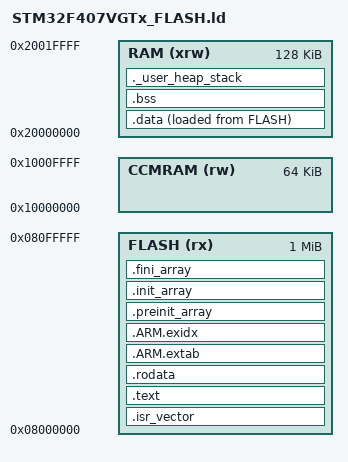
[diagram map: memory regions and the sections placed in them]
ENTRY(Reset_Handler)

_estack = ORIGIN(RAM) + LENGTH(RAM);
_Min_Heap_Size = 0x200;
_Min_Stack_Size = 0x800;

MEMORY
{
  FLASH (rx)  : ORIGIN = 0x08000000, LENGTH = 1024K
  /* SRAM1 (112 KiB) and SRAM2 (16 KiB) are contiguous. */
  RAM   (xrw) : ORIGIN = 0x20000000, LENGTH = 128K
  /* The remaining 64 KiB is core-coupled memory at a separate address. */
  CCMRAM (rw) : ORIGIN = 0x10000000, LENGTH = 64K
}

PHDRS
{
  flash PT_LOAD FLAGS(5);
  ram PT_LOAD FLAGS(6);
}

SECTIONS
{
  .isr_vector : { . = ALIGN(4); KEEP(*(.isr_vector)) . = ALIGN(4); } >FLASH :flash
  .text :
  {
    . = ALIGN(4);
    *(.text) *(.text*) *(.glue_7) *(.glue_7t) *(.eh_frame)
    KEEP(*(.init)) KEEP(*(.fini))
    . = ALIGN(4);
    _etext = .;
  } >FLASH
  .rodata : { . = ALIGN(4); *(.rodata) *(.rodata*) . = ALIGN(4); } >FLASH
  .ARM.extab : { *(.ARM.extab* .gnu.linkonce.armextab.*) } >FLASH
  .ARM.exidx : { __exidx_start = .; *(.ARM.exidx*) __exidx_end = .; } >FLASH
  .preinit_array : { PROVIDE_HIDDEN(__preinit_array_start = .); KEEP(*(.preinit_array*)) PROVIDE_HIDDEN(__preinit_array_end = .); } >FLASH
  .init_array : { PROVIDE_HIDDEN(__init_array_start = .); KEEP(*(SORT(.init_array.*))) KEEP(*(.init_array*)) PROVIDE_HIDDEN(__init_array_end = .); } >FLASH
  .fini_array : { PROVIDE_HIDDEN(__fini_array_start = .); KEEP(*(SORT(.fini_array.*))) KEEP(*(.fini_array*)) PROVIDE_HIDDEN(__fini_array_end = .); } >FLASH
  _sidata = LOADADDR(.data);
  .data :
  {
    . = ALIGN(4); _sdata = .;
    *(.data) *(.data*)
    . = ALIGN(4); _edata = .;
  } >RAM AT> FLASH :ram
  .bss (NOLOAD) :
  {
    . = ALIGN(4); _sbss = .; __bss_start__ = _sbss;
    *(.bss) *(.bss*) *(COMMON)
    . = ALIGN(4); _ebss = .; __bss_end__ = _ebss;
  } >RAM
  ._user_heap_stack (NOLOAD) :
  {
    . = ALIGN(8);
    PROVIDE(end = .); PROVIDE(_end = .);
    . = . + _Min_Heap_Size + _Min_Stack_Size;
    . = ALIGN(8);
  } >RAM
  .ARM.attributes 0 : { *(.ARM.attributes) }
}
